# STM32L4x6 register map
File version: 2.0
CPU: CM4 r0p1, little endian, MPU, FPU, 4 interrupt priority bits
Registers are 32-bit, read-write, reset 0x0 unless marked. A register's access mark holds for its fields unless they carry their own. Offsets are from the block's base; [hi:lo] are bit positions; {n}, {i} and the like mark numbered series.

## LCD — Liquid crystal display controller
Base 0x40002400
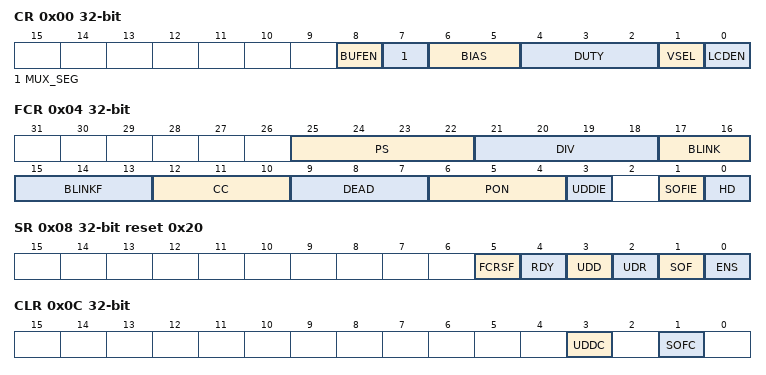
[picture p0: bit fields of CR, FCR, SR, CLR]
0x00 CR — LCD control register
  [8] BUFEN — Voltage output buffer enable This bit is used to enable/disable the voltage output buffer for higher driving capability.
  [7] MUX_SEG — Mux segment enable This bit is used to enable SEG pin remapping. Four SEG pins can be multiplexed with SEG[31:28] or SEG[15:12]. See Section19.3.7.
  [6:5] BIAS — Bias selector These bits determine the bias used. Value 11 is forbidden.
  [4:2] DUTY — Duty selection These bits determine the duty cycle.Unused COM pins can serve as general purpose input pins if COMIN is set. Values 101, 110 and 111 are forbidden. Others: Reserved
  [1] VSEL — Voltage source selection The VSEL bit determines the voltage source for the LCD.
  [0] LCDEN — LCD controller enable This bit is set by software to enable the LCD Controller/Driver. It is cleared by software to turn off the LCD at the beginning of the next frame. When the LCD is disabled all COM and SEG pins are driven to V<sub>SS</sub>.
0x04 FCR — LCD frame control register
  [25:22] PS — PS 16-bit prescaler
  [21:18] DIV — DIV clock divider
  [17:16] BLINK — Blink mode selection
  [15:13] BLINKF — Blink frequency selection
  [12:10] CC — Contrast control
  [9:7] DEAD — Dead time duration These bits are written by software to configure the length of the dead time between frames. During the dead time the COM and SEG voltage levels are held at 0 V to reduce the contrast without modifying the frame rate. ......
  [6:4] PON — Pulse ON duration These bits are written by software to define the pulse duration in terms of ck_ps pulses. Ashort pulse leads to lower power consumption, but displays with high internal resistance may need a longer pulse to achieve satisfactory contrast. Note that the pulse is never longer than one half prescaled LCD clock period. PON duration example with LCDCLK = 32.768kHz and PS=0x03:
  [3] UDDIE — Update display done interrupt enable This bit is set and cleared by software.
  [1] SOFIE — Start of frame interrupt enable This bit is set and cleared by software.
  [0] HD — High drive enable This bit is written by software to enable a low resistance divider. Displays with high internal resistance may need a longer drive time to achieve satisfactory contrast. This bit is useful in this case if some additional power consumption can be tolerated.
0x08 SR access per field reset 0x20 — LCD status register
  [5] FCRSF ro — LCD frame control register synchronization flag This bit is set by hardware each time the LCD_FCR register is updated in the LCDCLK domain. It is cleared by hardware when writing to the LCD_FCR register.
  [4] RDY ro — Ready flag This bit is set and cleared by hardware. It indicates the status of the step-up converter.
  [3] UDD ro — Update display done This bit is set by hardware. It is cleared by writing 1 to the UDDC bit in the LCD_CLR register. The bit set has priority over the clear. If the device is in Stop mode (PCLK not provided), UDD does not generate an interrupt even if UDDIE = 1. If the display is not enabled the UDD interrupt never occurs.
  [2] UDR rw — Update display request
  [1] SOF ro — Start-of-frame flag This bit is set by hardware at the beginning of a new frame, at the same time as the display data is updated. It is cleared by writing a 1 to the SOFC bit in the LCD_CLR register. The bit clear has priority over the set.
  [0] ENS ro — LCD enabled status This bit is set and cleared by hardware. It indicates the LCD controller status. The ENS bit is set immediately when the LCDEN bit in the LCD_CR goes from 0 to 1. On deactivation it reflects the real status of LCD so it becomes 0 at the end of the last displayed frame.
0x0C CLR wo — LCD clear register
  [3] UDDC — Update display done clear This bit is written by software to clear the UDD flag in the LCD_SR register.
  [1] SOFC — Start of frame flag clear This bit is written by software to clear the SOF flag in the LCD_SR register.
{0x14+8i} RAM_COM{i} 64-bit (reset mask 0xFFFFFFFF) (i=0..3) — LCD display memory
  [39:0] SEGS — Segment states, one bit per segment, LSB: S00, MSB: S39
{0x14+8i} RAM_COM{i} 64-bit (reset mask 0xFFFFFFFF) (i=4..7) — LCD display memory
  [43:0] SEGS — Segment states, one bit per segment, LSB: S00, MSB: S43
